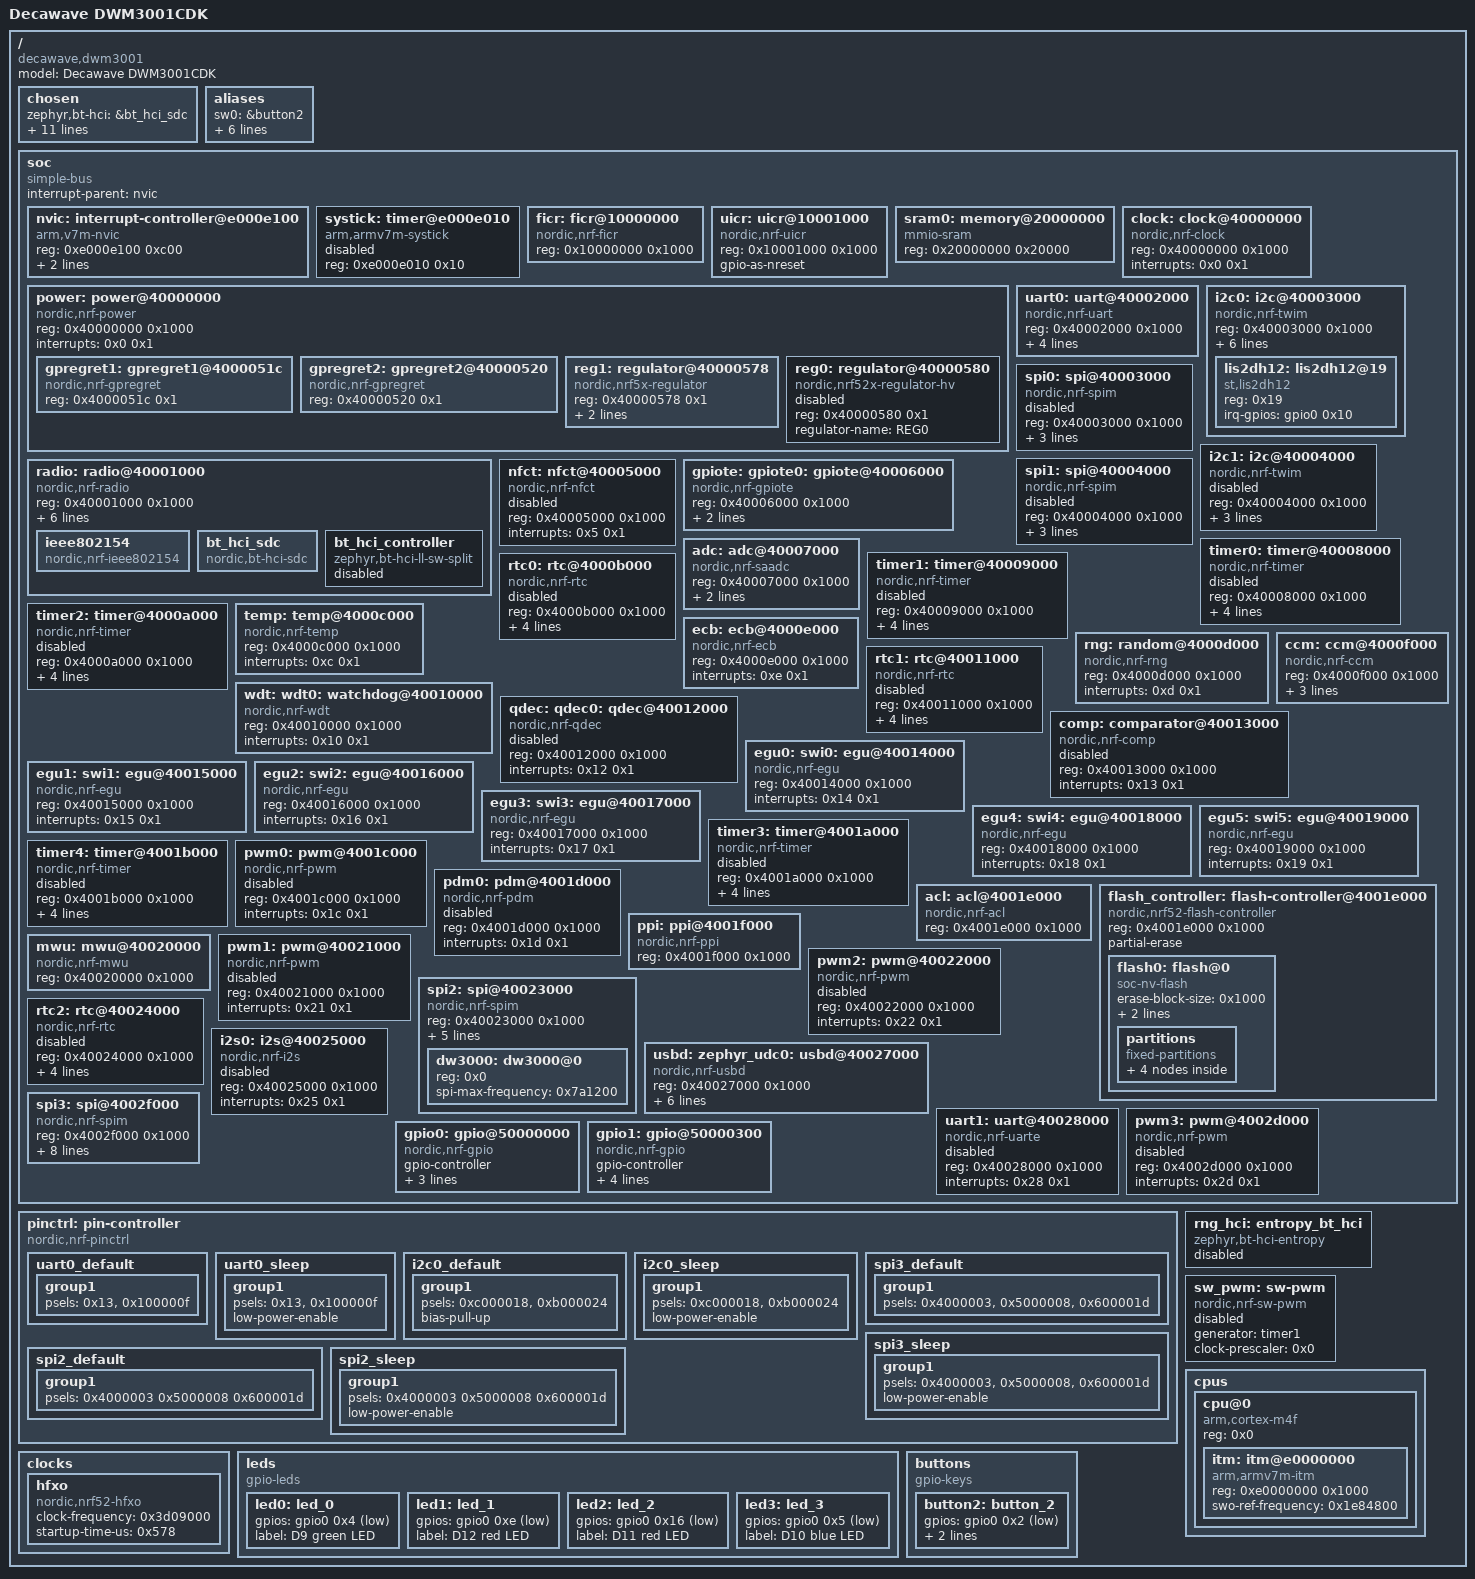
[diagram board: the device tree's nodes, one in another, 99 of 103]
/dts-v1/;

/* node '/' defined in zephyr\dts\common\skeleton.dtsi:9 */
/ {
	#address-cells = < 0x1 >;        /* in zephyr\dts\common\skeleton.dtsi:10 */
	#size-cells = < 0x1 >;           /* in zephyr\dts\common\skeleton.dtsi:11 */
	model = "Decawave DWM3001CDK";   /* in zephyr\boards\qorvo\decawave_dwm3001cdk\decawave_dwm3001cdk.dts:13 */
	compatible = "decawave,dwm3001"; /* in zephyr\boards\qorvo\decawave_dwm3001cdk\decawave_dwm3001cdk.dts:14 */

	/* node '/chosen' defined in zephyr\dts\common\skeleton.dtsi:13 */
	chosen {
		zephyr,bt-hci = &bt_hci_sdc;                 /* in zephyr\dts\arm\nordic\nrf52833.dtsi:14 */
		zephyr,entropy = &rng;                       /* in zephyr\dts\arm\nordic\nrf52833.dtsi:15 */
		zephyr,flash-controller = &flash_controller; /* in zephyr\dts\arm\nordic\nrf52833.dtsi:16 */
		zephyr,console = &uart0;                     /* in zephyr\boards\qorvo\decawave_dwm3001cdk\decawave_dwm3001cdk.dts:17 */
		zephyr,shell-uart = &uart0;                  /* in zephyr\boards\qorvo\decawave_dwm3001cdk\decawave_dwm3001cdk.dts:18 */
		zephyr,uart-mcumgr = &uart0;                 /* in zephyr\boards\qorvo\decawave_dwm3001cdk\decawave_dwm3001cdk.dts:19 */
		zephyr,bt-mon-uart = &uart0;                 /* in zephyr\boards\qorvo\decawave_dwm3001cdk\decawave_dwm3001cdk.dts:20 */
		zephyr,bt-c2h-uart = &uart0;                 /* in zephyr\boards\qorvo\decawave_dwm3001cdk\decawave_dwm3001cdk.dts:21 */
		zephyr,sram = &sram0;                        /* in zephyr\boards\qorvo\decawave_dwm3001cdk\decawave_dwm3001cdk.dts:22 */
		zephyr,flash = &flash0;                      /* in zephyr\boards\qorvo\decawave_dwm3001cdk\decawave_dwm3001cdk.dts:23 */
		zephyr,code-partition = &slot0_partition;    /* in zephyr\boards\qorvo\decawave_dwm3001cdk\decawave_dwm3001cdk.dts:24 */
		zephyr,ieee802154 = &ieee802154;             /* in zephyr\boards\qorvo\decawave_dwm3001cdk\decawave_dwm3001cdk.dts:25 */
	};

	/* node '/aliases' defined in zephyr\dts\common\skeleton.dtsi:15 */
	aliases {
		sw0 = &button2;     /* in zephyr\boards\qorvo\decawave_dwm3001cdk\decawave_dwm3001cdk.dts:69 */
		led0 = &led0;       /* in zephyr\boards\qorvo\decawave_dwm3001cdk\decawave_dwm3001cdk.dts:70 */
		led1 = &led1;       /* in zephyr\boards\qorvo\decawave_dwm3001cdk\decawave_dwm3001cdk.dts:71 */
		led2 = &led2;       /* in zephyr\boards\qorvo\decawave_dwm3001cdk\decawave_dwm3001cdk.dts:72 */
		led3 = &led3;       /* in zephyr\boards\qorvo\decawave_dwm3001cdk\decawave_dwm3001cdk.dts:73 */
		watchdog0 = &wdt0;  /* in zephyr\boards\qorvo\decawave_dwm3001cdk\decawave_dwm3001cdk.dts:74 */
		accel0 = &lis2dh12; /* in zephyr\boards\qorvo\decawave_dwm3001cdk\decawave_dwm3001cdk.dts:75 */
	};

	/* node '/soc' defined in zephyr\dts\arm\armv7-m.dtsi:6 */
	soc {
		#address-cells = < 0x1 >;     /* in zephyr\dts\arm\armv7-m.dtsi:7 */
		#size-cells = < 0x1 >;        /* in zephyr\dts\arm\armv7-m.dtsi:8 */
		interrupt-parent = < &nvic >; /* in zephyr\dts\arm\armv7-m.dtsi:10 */
		ranges;                       /* in zephyr\dts\arm\armv7-m.dtsi:11 */
		compatible = "simple-bus";    /* in zephyr\dts\arm\nordic\nrf52833_qdaa.dtsi:21 */

		/* node '/soc/interrupt-controller@e000e100' defined in zephyr\dts\arm\armv7-m.dtsi:13 */
		nvic: interrupt-controller@e000e100 {
			#address-cells = < 0x1 >;            /* in zephyr\dts\arm\armv7-m.dtsi:14 */
			compatible = "arm,v7m-nvic";         /* in zephyr\dts\arm\armv7-m.dtsi:15 */
			reg = < 0xe000e100 0xc00 >;          /* in zephyr\dts\arm\armv7-m.dtsi:16 */
			interrupt-controller;                /* in zephyr\dts\arm\armv7-m.dtsi:17 */
			#interrupt-cells = < 0x2 >;          /* in zephyr\dts\arm\armv7-m.dtsi:18 */
			arm,num-irq-priority-bits = < 0x3 >; /* in zephyr\dts\arm\nordic\nrf52833.dtsi:581 */
			phandle = < 0x1 >;                   /* in zephyr\dts\arm\armv7-m.dtsi:10 */
		};

		/* node '/soc/timer@e000e010' defined in zephyr\dts\arm\armv7-m.dtsi:21 */
		systick: timer@e000e010 {
			compatible = "arm,armv7m-systick"; /* in zephyr\dts\arm\armv7-m.dtsi:22 */
			reg = < 0xe000e010 0x10 >;         /* in zephyr\dts\arm\armv7-m.dtsi:23 */
			status = "disabled";               /* in zephyr\dts\arm\nordic\nrf52833.dtsi:586 */
		};

		/* node '/soc/ficr@10000000' defined in zephyr\dts\arm\nordic\nrf52833.dtsi:48 */
		ficr: ficr@10000000 {
			compatible = "nordic,nrf-ficr"; /* in zephyr\dts\arm\nordic\nrf52833.dtsi:49 */
			reg = < 0x10000000 0x1000 >;    /* in zephyr\dts\arm\nordic\nrf52833.dtsi:50 */
			#nordic,ficr-cells = < 0x1 >;   /* in zephyr\dts\arm\nordic\nrf52833.dtsi:51 */
			status = "okay";                /* in zephyr\dts\arm\nordic\nrf52833.dtsi:52 */
		};

		/* node '/soc/uicr@10001000' defined in zephyr\dts\arm\nordic\nrf52833.dtsi:55 */
		uicr: uicr@10001000 {
			compatible = "nordic,nrf-uicr";     /* in zephyr\dts\arm\nordic\nrf52833.dtsi:56 */
			reg = < 0x10001000 0x1000 >;        /* in zephyr\dts\arm\nordic\nrf52833.dtsi:57 */
			ranges = < 0x0 0x10001000 0x1000 >; /* in zephyr\dts\arm\nordic\nrf52833.dtsi:58 */
			status = "okay";                    /* in zephyr\dts\arm\nordic\nrf52833.dtsi:59 */
			#address-cells = < 0x1 >;           /* in zephyr\dts\arm\nordic\nrf52833.dtsi:60 */
			#size-cells = < 0x1 >;              /* in zephyr\dts\arm\nordic\nrf52833.dtsi:61 */
			gpio-as-nreset;                     /* in zephyr\boards\qorvo\decawave_dwm3001cdk\decawave_dwm3001cdk.dts:80 */
		};

		/* node '/soc/memory@20000000' defined in zephyr\dts\arm\nordic\nrf52833.dtsi:64 */
		sram0: memory@20000000 {
			compatible = "mmio-sram";            /* in zephyr\dts\arm\nordic\nrf52833.dtsi:65 */
			#address-cells = < 0x1 >;            /* in zephyr\dts\arm\nordic\nrf52833.dtsi:66 */
			#size-cells = < 0x1 >;               /* in zephyr\dts\arm\nordic\nrf52833.dtsi:67 */
			reg = < 0x20000000 0x20000 >;        /* in zephyr\dts\arm\nordic\nrf52833_qdaa.dtsi:15 */
			ranges = < 0x0 0x20000000 0x20000 >; /* in zephyr\dts\arm\nordic\nrf52833_qdaa.dtsi:16 */
		};

		/* node '/soc/clock@40000000' defined in zephyr\dts\arm\nordic\nrf52833.dtsi:70 */
		clock: clock@40000000 {
			compatible = "nordic,nrf-clock"; /* in zephyr\dts\arm\nordic\nrf52833.dtsi:71 */
			reg = < 0x40000000 0x1000 >;     /* in zephyr\dts\arm\nordic\nrf52833.dtsi:72 */
			interrupts = < 0x0 0x1 >;        /* in zephyr\dts\arm\nordic\nrf52833.dtsi:73 */
			status = "okay";                 /* in zephyr\dts\arm\nordic\nrf52833.dtsi:74 */
		};

		/* node '/soc/power@40000000' defined in zephyr\dts\arm\nordic\nrf52833.dtsi:77 */
		power: power@40000000 {
			compatible = "nordic,nrf-power"; /* in zephyr\dts\arm\nordic\nrf52833.dtsi:78 */
			reg = < 0x40000000 0x1000 >;     /* in zephyr\dts\arm\nordic\nrf52833.dtsi:79 */
			interrupts = < 0x0 0x1 >;        /* in zephyr\dts\arm\nordic\nrf52833.dtsi:80 */
			status = "okay";                 /* in zephyr\dts\arm\nordic\nrf52833.dtsi:81 */
			#address-cells = < 0x1 >;        /* in zephyr\dts\arm\nordic\nrf52833.dtsi:82 */
			#size-cells = < 0x1 >;           /* in zephyr\dts\arm\nordic\nrf52833.dtsi:83 */

			/* node '/soc/power@40000000/gpregret1@4000051c' defined in zephyr\dts\arm\nordic\nrf52833.dtsi:85 */
			gpregret1: gpregret1@4000051c {
				#address-cells = < 0x1 >;           /* in zephyr\dts\arm\nordic\nrf52833.dtsi:86 */
				#size-cells = < 0x1 >;              /* in zephyr\dts\arm\nordic\nrf52833.dtsi:87 */
				compatible = "nordic,nrf-gpregret"; /* in zephyr\dts\arm\nordic\nrf52833.dtsi:88 */
				reg = < 0x4000051c 0x1 >;           /* in zephyr\dts\arm\nordic\nrf52833.dtsi:89 */
				status = "okay";                    /* in zephyr\dts\arm\nordic\nrf52833.dtsi:90 */
			};

			/* node '/soc/power@40000000/gpregret2@40000520' defined in zephyr\dts\arm\nordic\nrf52833.dtsi:93 */
			gpregret2: gpregret2@40000520 {
				#address-cells = < 0x1 >;           /* in zephyr\dts\arm\nordic\nrf52833.dtsi:94 */
				#size-cells = < 0x1 >;              /* in zephyr\dts\arm\nordic\nrf52833.dtsi:95 */
				compatible = "nordic,nrf-gpregret"; /* in zephyr\dts\arm\nordic\nrf52833.dtsi:96 */
				reg = < 0x40000520 0x1 >;           /* in zephyr\dts\arm\nordic\nrf52833.dtsi:97 */
				status = "okay";                    /* in zephyr\dts\arm\nordic\nrf52833.dtsi:98 */
			};

			/* node '/soc/power@40000000/regulator@40000578' defined in zephyr\dts\arm\nordic\nrf52833.dtsi:101 */
			reg1: regulator@40000578 {
				compatible = "nordic,nrf5x-regulator"; /* in zephyr\dts\arm\nordic\nrf52833.dtsi:102 */
				reg = < 0x40000578 0x1 >;              /* in zephyr\dts\arm\nordic\nrf52833.dtsi:103 */
				regulator-name = "REG1";               /* in zephyr\dts\arm\nordic\nrf52833.dtsi:104 */
				regulator-initial-mode = < 0x1 >;      /* in zephyr\boards\qorvo\decawave_dwm3001cdk\decawave_dwm3001cdk.dts:168 */
			};

			/* node '/soc/power@40000000/regulator@40000580' defined in zephyr\dts\arm\nordic\nrf52833.dtsi:108 */
			reg0: regulator@40000580 {
				compatible = "nordic,nrf52x-regulator-hv"; /* in zephyr\dts\arm\nordic\nrf52833.dtsi:109 */
				reg = < 0x40000580 0x1 >;                  /* in zephyr\dts\arm\nordic\nrf52833.dtsi:110 */
				regulator-name = "REG0";                   /* in zephyr\dts\arm\nordic\nrf52833.dtsi:111 */
				status = "disabled";                       /* in zephyr\dts\arm\nordic\nrf52833.dtsi:112 */
			};
		};

		/* node '/soc/radio@40001000' defined in zephyr\dts\arm\nordic\nrf52833.dtsi:116 */
		radio: radio@40001000 {
			compatible = "nordic,nrf-radio"; /* in zephyr\dts\arm\nordic\nrf52833.dtsi:117 */
			reg = < 0x40001000 0x1000 >;     /* in zephyr\dts\arm\nordic\nrf52833.dtsi:118 */
			interrupts = < 0x1 0x1 >;        /* in zephyr\dts\arm\nordic\nrf52833.dtsi:119 */
			status = "okay";                 /* in zephyr\dts\arm\nordic\nrf52833.dtsi:120 */
			dfe-supported;                   /* in zephyr\dts\arm\nordic\nrf52833.dtsi:121 */
			ieee802154-supported;            /* in zephyr\dts\arm\nordic\nrf52833.dtsi:122 */
			ble-2mbps-supported;             /* in zephyr\dts\arm\nordic\nrf52833.dtsi:123 */
			ble-coded-phy-supported;         /* in zephyr\dts\arm\nordic\nrf52833.dtsi:124 */
			radio-tx-high-power-supported;   /* in zephyr\dts\arm\nordic\nrf52833.dtsi:125 */

			/* node '/soc/radio@40001000/ieee802154' defined in zephyr\dts\arm\nordic\nrf52833.dtsi:127 */
			ieee802154: ieee802154 {
				compatible = "nordic,nrf-ieee802154"; /* in zephyr\dts\arm\nordic\nrf52833.dtsi:128 */
				status = "okay";                      /* in zephyr\boards\qorvo\decawave_dwm3001cdk\decawave_dwm3001cdk.dts:131 */
			};

			/* node '/soc/radio@40001000/bt_hci_sdc' defined in zephyr\dts\arm\nordic\nrf52833.dtsi:132 */
			bt_hci_sdc: bt_hci_sdc {
				compatible = "nordic,bt-hci-sdc"; /* in zephyr\dts\arm\nordic\nrf52833.dtsi:133 */
				status = "okay";                  /* in zephyr\dts\arm\nordic\nrf52833.dtsi:134 */
			};

			/* node '/soc/radio@40001000/bt_hci_controller' defined in zephyr\dts\arm\nordic\nrf52833.dtsi:136 */
			bt_hci_controller: bt_hci_controller {
				compatible = "zephyr,bt-hci-ll-sw-split"; /* in zephyr\dts\arm\nordic\nrf52833.dtsi:137 */
				status = "disabled";                      /* in zephyr\dts\arm\nordic\nrf52833.dtsi:138 */
			};
		};

		/* node '/soc/uart@40002000' defined in zephyr\dts\arm\nordic\nrf52833.dtsi:142 */
		uart0: uart@40002000 {
			reg = < 0x40002000 0x1000 >;    /* in zephyr\dts\arm\nordic\nrf52833.dtsi:146 */
			interrupts = < 0x2 0x1 >;       /* in zephyr\dts\arm\nordic\nrf52833.dtsi:147 */
			status = "okay";                /* in zephyr\boards\qorvo\decawave_dwm3001cdk\decawave_dwm3001cdk.dts:92 */
			compatible = "nordic,nrf-uart"; /* in zephyr\boards\qorvo\decawave_dwm3001cdk\decawave_dwm3001cdk.dts:93 */
			current-speed = < 0x1c200 >;    /* in zephyr\boards\qorvo\decawave_dwm3001cdk\decawave_dwm3001cdk.dts:94 */
			pinctrl-0 = < &uart0_default >; /* in zephyr\boards\qorvo\decawave_dwm3001cdk\decawave_dwm3001cdk.dts:95 */
			pinctrl-1 = < &uart0_sleep >;   /* in zephyr\boards\qorvo\decawave_dwm3001cdk\decawave_dwm3001cdk.dts:96 */
			pinctrl-names = "default",
			                "sleep";        /* in zephyr\boards\qorvo\decawave_dwm3001cdk\decawave_dwm3001cdk.dts:97 */
		};

		/* node '/soc/i2c@40003000' defined in zephyr\dts\arm\nordic\nrf52833.dtsi:151 */
		i2c0: i2c@40003000 {
			#address-cells = < 0x1 >;       /* in zephyr\dts\arm\nordic\nrf52833.dtsi:160 */
			#size-cells = < 0x0 >;          /* in zephyr\dts\arm\nordic\nrf52833.dtsi:161 */
			reg = < 0x40003000 0x1000 >;    /* in zephyr\dts\arm\nordic\nrf52833.dtsi:162 */
			interrupts = < 0x3 0x1 >;       /* in zephyr\dts\arm\nordic\nrf52833.dtsi:163 */
			easydma-maxcnt-bits = < 0x10 >; /* in zephyr\dts\arm\nordic\nrf52833.dtsi:164 */
			zephyr,pm-device-runtime-auto;  /* in zephyr\dts\arm\nordic\nrf52833.dtsi:166 */
			compatible = "nordic,nrf-twim"; /* in zephyr\boards\qorvo\decawave_dwm3001cdk\decawave_dwm3001cdk.dts:105 */
			status = "okay";                /* in zephyr\boards\qorvo\decawave_dwm3001cdk\decawave_dwm3001cdk.dts:106 */
			clock-frequency = < 0x61a80 >;  /* in zephyr\boards\qorvo\decawave_dwm3001cdk\decawave_dwm3001cdk.dts:107 */
			pinctrl-0 = < &i2c0_default >;  /* in zephyr\boards\qorvo\decawave_dwm3001cdk\decawave_dwm3001cdk.dts:109 */
			pinctrl-1 = < &i2c0_sleep >;    /* in zephyr\boards\qorvo\decawave_dwm3001cdk\decawave_dwm3001cdk.dts:110 */
			pinctrl-names = "default",
			                "sleep";        /* in zephyr\boards\qorvo\decawave_dwm3001cdk\decawave_dwm3001cdk.dts:111 */

			/* node '/soc/i2c@40003000/lis2dh12@19' defined in zephyr\boards\qorvo\decawave_dwm3001cdk\decawave_dwm3001cdk.dts:113 */
			lis2dh12: lis2dh12@19 {
				compatible = "st,lis2dh12",
				             "st,lis2dh";        /* in zephyr\boards\qorvo\decawave_dwm3001cdk\decawave_dwm3001cdk.dts:114 */
				reg = < 0x19 >;                  /* in zephyr\boards\qorvo\decawave_dwm3001cdk\decawave_dwm3001cdk.dts:115 */
				irq-gpios = < &gpio0 0x10 0x0 >; /* in zephyr\boards\qorvo\decawave_dwm3001cdk\decawave_dwm3001cdk.dts:116 */
			};
		};

		/* node '/soc/spi@40003000' defined in zephyr\dts\arm\nordic\nrf52833.dtsi:169 */
		spi0: spi@40003000 {
			compatible = "nordic,nrf-spim"; /* in zephyr\dts\arm\nordic\nrf52833.dtsi:177 */
			#address-cells = < 0x1 >;       /* in zephyr\dts\arm\nordic\nrf52833.dtsi:178 */
			#size-cells = < 0x0 >;          /* in zephyr\dts\arm\nordic\nrf52833.dtsi:179 */
			reg = < 0x40003000 0x1000 >;    /* in zephyr\dts\arm\nordic\nrf52833.dtsi:180 */
			interrupts = < 0x3 0x1 >;       /* in zephyr\dts\arm\nordic\nrf52833.dtsi:181 */
			max-frequency = < 0x7a1200 >;   /* in zephyr\dts\arm\nordic\nrf52833.dtsi:182 */
			easydma-maxcnt-bits = < 0x10 >; /* in zephyr\dts\arm\nordic\nrf52833.dtsi:183 */
			status = "disabled";            /* in zephyr\dts\arm\nordic\nrf52833.dtsi:184 */
		};

		/* node '/soc/i2c@40004000' defined in zephyr\dts\arm\nordic\nrf52833.dtsi:187 */
		i2c1: i2c@40004000 {
			compatible = "nordic,nrf-twim"; /* in zephyr\dts\arm\nordic\nrf52833.dtsi:195 */
			#address-cells = < 0x1 >;       /* in zephyr\dts\arm\nordic\nrf52833.dtsi:196 */
			#size-cells = < 0x0 >;          /* in zephyr\dts\arm\nordic\nrf52833.dtsi:197 */
			reg = < 0x40004000 0x1000 >;    /* in zephyr\dts\arm\nordic\nrf52833.dtsi:198 */
			interrupts = < 0x4 0x1 >;       /* in zephyr\dts\arm\nordic\nrf52833.dtsi:199 */
			easydma-maxcnt-bits = < 0x10 >; /* in zephyr\dts\arm\nordic\nrf52833.dtsi:200 */
			status = "disabled";            /* in zephyr\dts\arm\nordic\nrf52833.dtsi:201 */
			zephyr,pm-device-runtime-auto;  /* in zephyr\dts\arm\nordic\nrf52833.dtsi:202 */
		};

		/* node '/soc/spi@40004000' defined in zephyr\dts\arm\nordic\nrf52833.dtsi:205 */
		spi1: spi@40004000 {
			compatible = "nordic,nrf-spim"; /* in zephyr\dts\arm\nordic\nrf52833.dtsi:213 */
			#address-cells = < 0x1 >;       /* in zephyr\dts\arm\nordic\nrf52833.dtsi:214 */
			#size-cells = < 0x0 >;          /* in zephyr\dts\arm\nordic\nrf52833.dtsi:215 */
			reg = < 0x40004000 0x1000 >;    /* in zephyr\dts\arm\nordic\nrf52833.dtsi:216 */
			interrupts = < 0x4 0x1 >;       /* in zephyr\dts\arm\nordic\nrf52833.dtsi:217 */
			max-frequency = < 0x7a1200 >;   /* in zephyr\dts\arm\nordic\nrf52833.dtsi:218 */
			easydma-maxcnt-bits = < 0x10 >; /* in zephyr\dts\arm\nordic\nrf52833.dtsi:219 */
			status = "disabled";            /* in zephyr\dts\arm\nordic\nrf52833.dtsi:220 */
		};

		/* node '/soc/nfct@40005000' defined in zephyr\dts\arm\nordic\nrf52833.dtsi:223 */
		nfct: nfct@40005000 {
			compatible = "nordic,nrf-nfct"; /* in zephyr\dts\arm\nordic\nrf52833.dtsi:224 */
			reg = < 0x40005000 0x1000 >;    /* in zephyr\dts\arm\nordic\nrf52833.dtsi:225 */
			interrupts = < 0x5 0x1 >;       /* in zephyr\dts\arm\nordic\nrf52833.dtsi:226 */
			status = "disabled";            /* in zephyr\dts\arm\nordic\nrf52833.dtsi:227 */
		};

		/* node '/soc/gpiote@40006000' defined in zephyr\dts\arm\nordic\nrf52833.dtsi:230 */
		gpiote: gpiote0: gpiote@40006000 {
			compatible = "nordic,nrf-gpiote"; /* in zephyr\dts\arm\nordic\nrf52833.dtsi:231 */
			reg = < 0x40006000 0x1000 >;      /* in zephyr\dts\arm\nordic\nrf52833.dtsi:232 */
			interrupts = < 0x6 0x5 >;         /* in zephyr\dts\arm\nordic\nrf52833.dtsi:233 */
			instance = < 0x0 >;               /* in zephyr\dts\arm\nordic\nrf52833.dtsi:235 */
			status = "okay";                  /* in zephyr\boards\qorvo\decawave_dwm3001cdk\decawave_dwm3001cdk.dts:84 */
			phandle = < 0xc >;                /* in zephyr\dts\arm\nordic\nrf52833.dtsi:563 */
		};

		/* node '/soc/adc@40007000' defined in zephyr\dts\arm\nordic\nrf52833.dtsi:238 */
		adc: adc@40007000 {
			compatible = "nordic,nrf-saadc"; /* in zephyr\dts\arm\nordic\nrf52833.dtsi:239 */
			reg = < 0x40007000 0x1000 >;     /* in zephyr\dts\arm\nordic\nrf52833.dtsi:240 */
			interrupts = < 0x7 0x1 >;        /* in zephyr\dts\arm\nordic\nrf52833.dtsi:241 */
			#io-channel-cells = < 0x1 >;     /* in zephyr\dts\arm\nordic\nrf52833.dtsi:243 */
			zephyr,pm-device-runtime-auto;   /* in zephyr\dts\arm\nordic\nrf52833.dtsi:244 */
			status = "okay";                 /* in zephyr\boards\qorvo\decawave_dwm3001cdk\decawave_dwm3001cdk.dts:172 */
		};

		/* node '/soc/timer@40008000' defined in zephyr\dts\arm\nordic\nrf52833.dtsi:247 */
		timer0: timer@40008000 {
			compatible = "nordic,nrf-timer"; /* in zephyr\dts\arm\nordic\nrf52833.dtsi:248 */
			status = "disabled";             /* in zephyr\dts\arm\nordic\nrf52833.dtsi:249 */
			reg = < 0x40008000 0x1000 >;     /* in zephyr\dts\arm\nordic\nrf52833.dtsi:250 */
			cc-num = < 0x4 >;                /* in zephyr\dts\arm\nordic\nrf52833.dtsi:251 */
			max-bit-width = < 0x20 >;        /* in zephyr\dts\arm\nordic\nrf52833.dtsi:252 */
			interrupts = < 0x8 0x1 >;        /* in zephyr\dts\arm\nordic\nrf52833.dtsi:253 */
			prescaler = < 0x0 >;             /* in zephyr\dts\arm\nordic\nrf52833.dtsi:254 */
		};

		/* node '/soc/timer@40009000' defined in zephyr\dts\arm\nordic\nrf52833.dtsi:257 */
		timer1: timer@40009000 {
			compatible = "nordic,nrf-timer"; /* in zephyr\dts\arm\nordic\nrf52833.dtsi:258 */
			status = "disabled";             /* in zephyr\dts\arm\nordic\nrf52833.dtsi:259 */
			reg = < 0x40009000 0x1000 >;     /* in zephyr\dts\arm\nordic\nrf52833.dtsi:260 */
			cc-num = < 0x4 >;                /* in zephyr\dts\arm\nordic\nrf52833.dtsi:261 */
			max-bit-width = < 0x20 >;        /* in zephyr\dts\arm\nordic\nrf52833.dtsi:262 */
			interrupts = < 0x9 0x1 >;        /* in zephyr\dts\arm\nordic\nrf52833.dtsi:263 */
			prescaler = < 0x0 >;             /* in zephyr\dts\arm\nordic\nrf52833.dtsi:264 */
			phandle = < 0xd >;               /* in zephyr\dts\vendor\nordic\nrf_common.dtsi:42 */
		};

		/* node '/soc/timer@4000a000' defined in zephyr\dts\arm\nordic\nrf52833.dtsi:267 */
		timer2: timer@4000a000 {
			compatible = "nordic,nrf-timer"; /* in zephyr\dts\arm\nordic\nrf52833.dtsi:268 */
			status = "disabled";             /* in zephyr\dts\arm\nordic\nrf52833.dtsi:269 */
			reg = < 0x4000a000 0x1000 >;     /* in zephyr\dts\arm\nordic\nrf52833.dtsi:270 */
			cc-num = < 0x4 >;                /* in zephyr\dts\arm\nordic\nrf52833.dtsi:271 */
			max-bit-width = < 0x20 >;        /* in zephyr\dts\arm\nordic\nrf52833.dtsi:272 */
			interrupts = < 0xa 0x1 >;        /* in zephyr\dts\arm\nordic\nrf52833.dtsi:273 */
			prescaler = < 0x0 >;             /* in zephyr\dts\arm\nordic\nrf52833.dtsi:274 */
		};

		/* node '/soc/rtc@4000b000' defined in zephyr\dts\arm\nordic\nrf52833.dtsi:277 */
		rtc0: rtc@4000b000 {
			compatible = "nordic,nrf-rtc"; /* in zephyr\dts\arm\nordic\nrf52833.dtsi:278 */
			reg = < 0x4000b000 0x1000 >;   /* in zephyr\dts\arm\nordic\nrf52833.dtsi:279 */
			cc-num = < 0x3 >;              /* in zephyr\dts\arm\nordic\nrf52833.dtsi:280 */
			interrupts = < 0xb 0x1 >;      /* in zephyr\dts\arm\nordic\nrf52833.dtsi:281 */
			status = "disabled";           /* in zephyr\dts\arm\nordic\nrf52833.dtsi:282 */
			clock-frequency = < 0x8000 >;  /* in zephyr\dts\arm\nordic\nrf52833.dtsi:283 */
			prescaler = < 0x1 >;           /* in zephyr\dts\arm\nordic\nrf52833.dtsi:284 */
		};

		/* node '/soc/temp@4000c000' defined in zephyr\dts\arm\nordic\nrf52833.dtsi:287 */
		temp: temp@4000c000 {
			compatible = "nordic,nrf-temp"; /* in zephyr\dts\arm\nordic\nrf52833.dtsi:288 */
			reg = < 0x4000c000 0x1000 >;    /* in zephyr\dts\arm\nordic\nrf52833.dtsi:289 */
			interrupts = < 0xc 0x1 >;       /* in zephyr\dts\arm\nordic\nrf52833.dtsi:290 */
			status = "okay";                /* in zephyr\dts\arm\nordic\nrf52833.dtsi:291 */
		};

		/* node '/soc/random@4000d000' defined in zephyr\dts\arm\nordic\nrf52833.dtsi:294 */
		rng: random@4000d000 {
			compatible = "nordic,nrf-rng"; /* in zephyr\dts\arm\nordic\nrf52833.dtsi:295 */
			reg = < 0x4000d000 0x1000 >;   /* in zephyr\dts\arm\nordic\nrf52833.dtsi:296 */
			interrupts = < 0xd 0x1 >;      /* in zephyr\dts\arm\nordic\nrf52833.dtsi:297 */
			status = "okay";               /* in zephyr\dts\arm\nordic\nrf52833.dtsi:298 */
		};

		/* node '/soc/ecb@4000e000' defined in zephyr\dts\arm\nordic\nrf52833.dtsi:301 */
		ecb: ecb@4000e000 {
			compatible = "nordic,nrf-ecb"; /* in zephyr\dts\arm\nordic\nrf52833.dtsi:302 */
			reg = < 0x4000e000 0x1000 >;   /* in zephyr\dts\arm\nordic\nrf52833.dtsi:303 */
			interrupts = < 0xe 0x1 >;      /* in zephyr\dts\arm\nordic\nrf52833.dtsi:304 */
			status = "okay";               /* in zephyr\dts\arm\nordic\nrf52833.dtsi:305 */
		};

		/* node '/soc/ccm@4000f000' defined in zephyr\dts\arm\nordic\nrf52833.dtsi:308 */
		ccm: ccm@4000f000 {
			compatible = "nordic,nrf-ccm"; /* in zephyr\dts\arm\nordic\nrf52833.dtsi:309 */
			reg = < 0x4000f000 0x1000 >;   /* in zephyr\dts\arm\nordic\nrf52833.dtsi:310 */
			interrupts = < 0xf 0x1 >;      /* in zephyr\dts\arm\nordic\nrf52833.dtsi:311 */
			length-field-length-8-bits;    /* in zephyr\dts\arm\nordic\nrf52833.dtsi:312 */
			headermask-supported;          /* in zephyr\dts\arm\nordic\nrf52833.dtsi:313 */
			status = "okay";               /* in zephyr\dts\arm\nordic\nrf52833.dtsi:314 */
		};

		/* node '/soc/watchdog@40010000' defined in zephyr\dts\arm\nordic\nrf52833.dtsi:317 */
		wdt: wdt0: watchdog@40010000 {
			compatible = "nordic,nrf-wdt"; /* in zephyr\dts\arm\nordic\nrf52833.dtsi:318 */
			reg = < 0x40010000 0x1000 >;   /* in zephyr\dts\arm\nordic\nrf52833.dtsi:319 */
			interrupts = < 0x10 0x1 >;     /* in zephyr\dts\arm\nordic\nrf52833.dtsi:320 */
			status = "okay";               /* in zephyr\dts\arm\nordic\nrf52833.dtsi:321 */
		};

		/* node '/soc/rtc@40011000' defined in zephyr\dts\arm\nordic\nrf52833.dtsi:324 */
		rtc1: rtc@40011000 {
			compatible = "nordic,nrf-rtc"; /* in zephyr\dts\arm\nordic\nrf52833.dtsi:325 */
			reg = < 0x40011000 0x1000 >;   /* in zephyr\dts\arm\nordic\nrf52833.dtsi:326 */
			cc-num = < 0x4 >;              /* in zephyr\dts\arm\nordic\nrf52833.dtsi:327 */
			interrupts = < 0x11 0x1 >;     /* in zephyr\dts\arm\nordic\nrf52833.dtsi:328 */
			status = "disabled";           /* in zephyr\dts\arm\nordic\nrf52833.dtsi:329 */
			clock-frequency = < 0x8000 >;  /* in zephyr\dts\arm\nordic\nrf52833.dtsi:330 */
			prescaler = < 0x1 >;           /* in zephyr\dts\arm\nordic\nrf52833.dtsi:331 */
		};

		/* node '/soc/qdec@40012000' defined in zephyr\dts\arm\nordic\nrf52833.dtsi:334 */
		qdec: qdec0: qdec@40012000 {
			compatible = "nordic,nrf-qdec"; /* in zephyr\dts\arm\nordic\nrf52833.dtsi:335 */
			reg = < 0x40012000 0x1000 >;    /* in zephyr\dts\arm\nordic\nrf52833.dtsi:336 */
			interrupts = < 0x12 0x1 >;      /* in zephyr\dts\arm\nordic\nrf52833.dtsi:337 */
			status = "disabled";            /* in zephyr\dts\arm\nordic\nrf52833.dtsi:338 */
		};

		/* node '/soc/comparator@40013000' defined in zephyr\dts\arm\nordic\nrf52833.dtsi:341 */
		comp: comparator@40013000 {
			compatible = "nordic,nrf-comp"; /* in zephyr\dts\arm\nordic\nrf52833.dtsi:346 */
			reg = < 0x40013000 0x1000 >;    /* in zephyr\dts\arm\nordic\nrf52833.dtsi:347 */
			interrupts = < 0x13 0x1 >;      /* in zephyr\dts\arm\nordic\nrf52833.dtsi:348 */
			status = "disabled";            /* in zephyr\dts\arm\nordic\nrf52833.dtsi:349 */
		};

		/* node '/soc/egu@40014000' defined in zephyr\dts\arm\nordic\nrf52833.dtsi:352 */
		egu0: swi0: egu@40014000 {
			compatible = "nordic,nrf-egu",
			             "nordic,nrf-swi"; /* in zephyr\dts\arm\nordic\nrf52833.dtsi:353 */
			reg = < 0x40014000 0x1000 >;   /* in zephyr\dts\arm\nordic\nrf52833.dtsi:354 */
			interrupts = < 0x14 0x1 >;     /* in zephyr\dts\arm\nordic\nrf52833.dtsi:355 */
			status = "okay";               /* in zephyr\dts\arm\nordic\nrf52833.dtsi:356 */
		};

		/* node '/soc/egu@40015000' defined in zephyr\dts\arm\nordic\nrf52833.dtsi:359 */
		egu1: swi1: egu@40015000 {
			compatible = "nordic,nrf-egu",
			             "nordic,nrf-swi"; /* in zephyr\dts\arm\nordic\nrf52833.dtsi:360 */
			reg = < 0x40015000 0x1000 >;   /* in zephyr\dts\arm\nordic\nrf52833.dtsi:361 */
			interrupts = < 0x15 0x1 >;     /* in zephyr\dts\arm\nordic\nrf52833.dtsi:362 */
			status = "okay";               /* in zephyr\dts\arm\nordic\nrf52833.dtsi:363 */
		};

		/* node '/soc/egu@40016000' defined in zephyr\dts\arm\nordic\nrf52833.dtsi:366 */
		egu2: swi2: egu@40016000 {
			compatible = "nordic,nrf-egu",
			             "nordic,nrf-swi"; /* in zephyr\dts\arm\nordic\nrf52833.dtsi:367 */
			reg = < 0x40016000 0x1000 >;   /* in zephyr\dts\arm\nordic\nrf52833.dtsi:368 */
			interrupts = < 0x16 0x1 >;     /* in zephyr\dts\arm\nordic\nrf52833.dtsi:369 */
			status = "okay";               /* in zephyr\dts\arm\nordic\nrf52833.dtsi:370 */
		};

		/* node '/soc/egu@40017000' defined in zephyr\dts\arm\nordic\nrf52833.dtsi:373 */
		egu3: swi3: egu@40017000 {
			compatible = "nordic,nrf-egu",
			             "nordic,nrf-swi"; /* in zephyr\dts\arm\nordic\nrf52833.dtsi:374 */
			reg = < 0x40017000 0x1000 >;   /* in zephyr\dts\arm\nordic\nrf52833.dtsi:375 */
			interrupts = < 0x17 0x1 >;     /* in zephyr\dts\arm\nordic\nrf52833.dtsi:376 */
			status = "okay";               /* in zephyr\dts\arm\nordic\nrf52833.dtsi:377 */
		};

		/* node '/soc/egu@40018000' defined in zephyr\dts\arm\nordic\nrf52833.dtsi:380 */
		egu4: swi4: egu@40018000 {
			compatible = "nordic,nrf-egu",
			             "nordic,nrf-swi"; /* in zephyr\dts\arm\nordic\nrf52833.dtsi:381 */
			reg = < 0x40018000 0x1000 >;   /* in zephyr\dts\arm\nordic\nrf52833.dtsi:382 */
			interrupts = < 0x18 0x1 >;     /* in zephyr\dts\arm\nordic\nrf52833.dtsi:383 */
			status = "okay";               /* in zephyr\dts\arm\nordic\nrf52833.dtsi:384 */
		};

		/* node '/soc/egu@40019000' defined in zephyr\dts\arm\nordic\nrf52833.dtsi:387 */
		egu5: swi5: egu@40019000 {
			compatible = "nordic,nrf-egu",
			             "nordic,nrf-swi"; /* in zephyr\dts\arm\nordic\nrf52833.dtsi:388 */
			reg = < 0x40019000 0x1000 >;   /* in zephyr\dts\arm\nordic\nrf52833.dtsi:389 */
			interrupts = < 0x19 0x1 >;     /* in zephyr\dts\arm\nordic\nrf52833.dtsi:390 */
			status = "okay";               /* in zephyr\dts\arm\nordic\nrf52833.dtsi:391 */
		};

		/* node '/soc/timer@4001a000' defined in zephyr\dts\arm\nordic\nrf52833.dtsi:394 */
		timer3: timer@4001a000 {
			compatible = "nordic,nrf-timer"; /* in zephyr\dts\arm\nordic\nrf52833.dtsi:395 */
			status = "disabled";             /* in zephyr\dts\arm\nordic\nrf52833.dtsi:396 */
			reg = < 0x4001a000 0x1000 >;     /* in zephyr\dts\arm\nordic\nrf52833.dtsi:397 */
			cc-num = < 0x6 >;                /* in zephyr\dts\arm\nordic\nrf52833.dtsi:398 */
			max-bit-width = < 0x20 >;        /* in zephyr\dts\arm\nordic\nrf52833.dtsi:399 */
			interrupts = < 0x1a 0x1 >;       /* in zephyr\dts\arm\nordic\nrf52833.dtsi:400 */
			prescaler = < 0x0 >;             /* in zephyr\dts\arm\nordic\nrf52833.dtsi:401 */
		};

		/* node '/soc/timer@4001b000' defined in zephyr\dts\arm\nordic\nrf52833.dtsi:404 */
		timer4: timer@4001b000 {
			compatible = "nordic,nrf-timer"; /* in zephyr\dts\arm\nordic\nrf52833.dtsi:405 */
			status = "disabled";             /* in zephyr\dts\arm\nordic\nrf52833.dtsi:406 */
			reg = < 0x4001b000 0x1000 >;     /* in zephyr\dts\arm\nordic\nrf52833.dtsi:407 */
			cc-num = < 0x6 >;                /* in zephyr\dts\arm\nordic\nrf52833.dtsi:408 */
			max-bit-width = < 0x20 >;        /* in zephyr\dts\arm\nordic\nrf52833.dtsi:409 */
			interrupts = < 0x1b 0x1 >;       /* in zephyr\dts\arm\nordic\nrf52833.dtsi:410 */
			prescaler = < 0x0 >;             /* in zephyr\dts\arm\nordic\nrf52833.dtsi:411 */
		};

		/* node '/soc/pwm@4001c000' defined in zephyr\dts\arm\nordic\nrf52833.dtsi:414 */
		pwm0: pwm@4001c000 {
			compatible = "nordic,nrf-pwm"; /* in zephyr\dts\arm\nordic\nrf52833.dtsi:415 */
			reg = < 0x4001c000 0x1000 >;   /* in zephyr\dts\arm\nordic\nrf52833.dtsi:416 */
			interrupts = < 0x1c 0x1 >;     /* in zephyr\dts\arm\nordic\nrf52833.dtsi:417 */
			status = "disabled";           /* in zephyr\dts\arm\nordic\nrf52833.dtsi:418 */
			#pwm-cells = < 0x3 >;          /* in zephyr\dts\arm\nordic\nrf52833.dtsi:419 */
		};

		/* node '/soc/pdm@4001d000' defined in zephyr\dts\arm\nordic\nrf52833.dtsi:422 */
		pdm0: pdm@4001d000 {
			compatible = "nordic,nrf-pdm"; /* in zephyr\dts\arm\nordic\nrf52833.dtsi:423 */
			reg = < 0x4001d000 0x1000 >;   /* in zephyr\dts\arm\nordic\nrf52833.dtsi:424 */
			interrupts = < 0x1d 0x1 >;     /* in zephyr\dts\arm\nordic\nrf52833.dtsi:425 */
			status = "disabled";           /* in zephyr\dts\arm\nordic\nrf52833.dtsi:426 */
		};

		/* node '/soc/acl@4001e000' defined in zephyr\dts\arm\nordic\nrf52833.dtsi:429 */
		acl: acl@4001e000 {
			compatible = "nordic,nrf-acl"; /* in zephyr\dts\arm\nordic\nrf52833.dtsi:430 */
			reg = < 0x4001e000 0x1000 >;   /* in zephyr\dts\arm\nordic\nrf52833.dtsi:431 */
			status = "okay";               /* in zephyr\dts\arm\nordic\nrf52833.dtsi:432 */
		};

		/* node '/soc/flash-controller@4001e000' defined in zephyr\dts\arm\nordic\nrf52833.dtsi:435 */
		flash_controller: flash-controller@4001e000 {
			compatible = "nordic,nrf52-flash-controller"; /* in zephyr\dts\arm\nordic\nrf52833.dtsi:436 */
			reg = < 0x4001e000 0x1000 >;                  /* in zephyr\dts\arm\nordic\nrf52833.dtsi:437 */
			partial-erase;                                /* in zephyr\dts\arm\nordic\nrf52833.dtsi:438 */
			#address-cells = < 0x1 >;                     /* in zephyr\dts\arm\nordic\nrf52833.dtsi:440 */
			#size-cells = < 0x1 >;                        /* in zephyr\dts\arm\nordic\nrf52833.dtsi:441 */

			/* node '/soc/flash-controller@4001e000/flash@0' defined in zephyr\dts\arm\nordic\nrf52833.dtsi:443 */
			flash0: flash@0 {
				compatible = "soc-nv-flash";   /* in zephyr\dts\arm\nordic\nrf52833.dtsi:444 */
				erase-block-size = < 0x1000 >; /* in zephyr\dts\arm\nordic\nrf52833.dtsi:445 */
				write-block-size = < 0x4 >;    /* in zephyr\dts\arm\nordic\nrf52833.dtsi:446 */
				reg = < 0x0 0x80000 >;         /* in zephyr\dts\arm\nordic\nrf52833_qdaa.dtsi:11 */

				/* node '/soc/flash-controller@4001e000/flash@0/partitions' defined in zephyr\boards\qorvo\decawave_dwm3001cdk\decawave_dwm3001cdk.dts:135 */
				partitions {
					compatible = "fixed-partitions"; /* in zephyr\boards\qorvo\decawave_dwm3001cdk\decawave_dwm3001cdk.dts:136 */
					#address-cells = < 0x1 >;        /* in zephyr\boards\qorvo\decawave_dwm3001cdk\decawave_dwm3001cdk.dts:137 */
					#size-cells = < 0x1 >;           /* in zephyr\boards\qorvo\decawave_dwm3001cdk\decawave_dwm3001cdk.dts:138 */

					/* node '/soc/flash-controller@4001e000/flash@0/partitions/partition@0' defined in zephyr\boards\qorvo\decawave_dwm3001cdk\decawave_dwm3001cdk.dts:140 */
					boot_partition: partition@0 {
						label = "mcuboot";    /* in zephyr\boards\qorvo\decawave_dwm3001cdk\decawave_dwm3001cdk.dts:141 */
						reg = < 0x0 0xc000 >; /* in zephyr\boards\qorvo\decawave_dwm3001cdk\decawave_dwm3001cdk.dts:142 */
					};

					/* node '/soc/flash-controller@4001e000/flash@0/partitions/partition@c000' defined in zephyr\boards\qorvo\decawave_dwm3001cdk\decawave_dwm3001cdk.dts:145 */
					slot0_partition: partition@c000 {
						label = "image-0";        /* in zephyr\boards\qorvo\decawave_dwm3001cdk\decawave_dwm3001cdk.dts:146 */
						reg = < 0xc000 0x38000 >; /* in zephyr\boards\qorvo\decawave_dwm3001cdk\decawave_dwm3001cdk.dts:147 */
					};

					/* node '/soc/flash-controller@4001e000/flash@0/partitions/partition@44000' defined in zephyr\boards\qorvo\decawave_dwm3001cdk\decawave_dwm3001cdk.dts:150 */
					slot1_partition: partition@44000 {
						label = "image-1";         /* in zephyr\boards\qorvo\decawave_dwm3001cdk\decawave_dwm3001cdk.dts:151 */
						reg = < 0x44000 0x36000 >; /* in zephyr\boards\qorvo\decawave_dwm3001cdk\decawave_dwm3001cdk.dts:152 */
					};

					/* node '/soc/flash-controller@4001e000/flash@0/partitions/partition@7a000' defined in zephyr\boards\qorvo\decawave_dwm3001cdk\decawave_dwm3001cdk.dts:155 */
					storage_partition: partition@7a000 {
						label = "storage";        /* in zephyr\boards\qorvo\decawave_dwm3001cdk\decawave_dwm3001cdk.dts:156 */
						reg = < 0x7a000 0x6000 >; /* in zephyr\boards\qorvo\decawave_dwm3001cdk\decawave_dwm3001cdk.dts:157 */
					};
				};
			};
		};

		/* node '/soc/ppi@4001f000' defined in zephyr\dts\arm\nordic\nrf52833.dtsi:450 */
		ppi: ppi@4001f000 {
			compatible = "nordic,nrf-ppi"; /* in zephyr\dts\arm\nordic\nrf52833.dtsi:451 */
			reg = < 0x4001f000 0x1000 >;   /* in zephyr\dts\arm\nordic\nrf52833.dtsi:452 */
			status = "okay";               /* in zephyr\dts\arm\nordic\nrf52833.dtsi:453 */
		};

		/* node '/soc/mwu@40020000' defined in zephyr\dts\arm\nordic\nrf52833.dtsi:456 */
		mwu: mwu@40020000 {
			compatible = "nordic,nrf-mwu"; /* in zephyr\dts\arm\nordic\nrf52833.dtsi:457 */
			reg = < 0x40020000 0x1000 >;   /* in zephyr\dts\arm\nordic\nrf52833.dtsi:458 */
			status = "okay";               /* in zephyr\dts\arm\nordic\nrf52833.dtsi:459 */
		};

		/* node '/soc/pwm@40021000' defined in zephyr\dts\arm\nordic\nrf52833.dtsi:462 */
		pwm1: pwm@40021000 {
			compatible = "nordic,nrf-pwm"; /* in zephyr\dts\arm\nordic\nrf52833.dtsi:463 */
			reg = < 0x40021000 0x1000 >;   /* in zephyr\dts\arm\nordic\nrf52833.dtsi:464 */
			interrupts = < 0x21 0x1 >;     /* in zephyr\dts\arm\nordic\nrf52833.dtsi:465 */
			status = "disabled";           /* in zephyr\dts\arm\nordic\nrf52833.dtsi:466 */
			#pwm-cells = < 0x3 >;          /* in zephyr\dts\arm\nordic\nrf52833.dtsi:467 */
		};

		/* node '/soc/pwm@40022000' defined in zephyr\dts\arm\nordic\nrf52833.dtsi:470 */
		pwm2: pwm@40022000 {
			compatible = "nordic,nrf-pwm"; /* in zephyr\dts\arm\nordic\nrf52833.dtsi:471 */
			reg = < 0x40022000 0x1000 >;   /* in zephyr\dts\arm\nordic\nrf52833.dtsi:472 */
			interrupts = < 0x22 0x1 >;     /* in zephyr\dts\arm\nordic\nrf52833.dtsi:473 */
			status = "disabled";           /* in zephyr\dts\arm\nordic\nrf52833.dtsi:474 */
			#pwm-cells = < 0x3 >;          /* in zephyr\dts\arm\nordic\nrf52833.dtsi:475 */
		};

		/* node '/soc/spi@40023000' defined in zephyr\dts\arm\nordic\nrf52833.dtsi:478 */
		spi2: spi@40023000 {
			#address-cells = < 0x1 >;       /* in zephyr\dts\arm\nordic\nrf52833.dtsi:487 */
			#size-cells = < 0x0 >;          /* in zephyr\dts\arm\nordic\nrf52833.dtsi:488 */
			reg = < 0x40023000 0x1000 >;    /* in zephyr\dts\arm\nordic\nrf52833.dtsi:489 */
			interrupts = < 0x23 0x1 >;      /* in zephyr\dts\arm\nordic\nrf52833.dtsi:490 */
			max-frequency = < 0x7a1200 >;   /* in zephyr\dts\arm\nordic\nrf52833.dtsi:491 */
			easydma-maxcnt-bits = < 0x10 >; /* in zephyr\dts\arm\nordic\nrf52833.dtsi:492 */
			compatible = "nordic,nrf-spim"; /* in ..\..\_Work\GitHub\PinTracker_NRF\pintracker_app\boards\decawave_dwm3001cdk.overlay:2 */
			status = "okay";                /* in ..\..\_Work\GitHub\PinTracker_NRF\pintracker_app\boards\decawave_dwm3001cdk.overlay:3 */
			pinctrl-0 = < &spi2_default >;  /* in ..\..\_Work\GitHub\PinTracker_NRF\pintracker_app\boards\decawave_dwm3001cdk.overlay:5 */
			pinctrl-1 = < &spi2_sleep >;    /* in ..\..\_Work\GitHub\PinTracker_NRF\pintracker_app\boards\decawave_dwm3001cdk.overlay:6 */
			pinctrl-names = "default",
			                "sleep";        /* in ..\..\_Work\GitHub\PinTracker_NRF\pintracker_app\boards\decawave_dwm3001cdk.overlay:7 */

			/* node '/soc/spi@40023000/dw3000@0' defined in ..\..\_Work\GitHub\PinTracker_NRF\pintracker_app\boards\decawave_dwm3001cdk.overlay:9 */
			dw3000: dw3000@0 {
				reg = < 0x0 >;                    /* in ..\..\_Work\GitHub\PinTracker_NRF\pintracker_app\boards\decawave_dwm3001cdk.overlay:10 */
				spi-max-frequency = < 0x7a1200 >; /* in ..\..\_Work\GitHub\PinTracker_NRF\pintracker_app\boards\decawave_dwm3001cdk.overlay:11 */
			};
		};

		/* node '/soc/rtc@40024000' defined in zephyr\dts\arm\nordic\nrf52833.dtsi:496 */
		rtc2: rtc@40024000 {
			compatible = "nordic,nrf-rtc"; /* in zephyr\dts\arm\nordic\nrf52833.dtsi:497 */
			reg = < 0x40024000 0x1000 >;   /* in zephyr\dts\arm\nordic\nrf52833.dtsi:498 */
			cc-num = < 0x4 >;              /* in zephyr\dts\arm\nordic\nrf52833.dtsi:499 */
			interrupts = < 0x24 0x1 >;     /* in zephyr\dts\arm\nordic\nrf52833.dtsi:500 */
			status = "disabled";           /* in zephyr\dts\arm\nordic\nrf52833.dtsi:501 */
			clock-frequency = < 0x8000 >;  /* in zephyr\dts\arm\nordic\nrf52833.dtsi:502 */
			prescaler = < 0x1 >;           /* in zephyr\dts\arm\nordic\nrf52833.dtsi:503 */
		};

		/* node '/soc/i2s@40025000' defined in zephyr\dts\arm\nordic\nrf52833.dtsi:506 */
		i2s0: i2s@40025000 {
			compatible = "nordic,nrf-i2s"; /* in zephyr\dts\arm\nordic\nrf52833.dtsi:507 */
			#address-cells = < 0x1 >;      /* in zephyr\dts\arm\nordic\nrf52833.dtsi:508 */
			#size-cells = < 0x0 >;         /* in zephyr\dts\arm\nordic\nrf52833.dtsi:509 */
			reg = < 0x40025000 0x1000 >;   /* in zephyr\dts\arm\nordic\nrf52833.dtsi:510 */
			interrupts = < 0x25 0x1 >;     /* in zephyr\dts\arm\nordic\nrf52833.dtsi:511 */
			status = "disabled";           /* in zephyr\dts\arm\nordic\nrf52833.dtsi:512 */
		};

		/* node '/soc/usbd@40027000' defined in zephyr\dts\arm\nordic\nrf52833.dtsi:515 */
		usbd: zephyr_udc0: usbd@40027000 {
			reg = < 0x40027000 0x1000 >;    /* in zephyr\dts\arm\nordic\nrf52833.dtsi:517 */
			interrupts = < 0x27 0x1 >;      /* in zephyr\dts\arm\nordic\nrf52833.dtsi:518 */
			num-bidir-endpoints = < 0x1 >;  /* in zephyr\dts\arm\nordic\nrf52833.dtsi:519 */
			num-in-endpoints = < 0x7 >;     /* in zephyr\dts\arm\nordic\nrf52833.dtsi:520 */
			num-out-endpoints = < 0x7 >;    /* in zephyr\dts\arm\nordic\nrf52833.dtsi:521 */
			num-isoin-endpoints = < 0x1 >;  /* in zephyr\dts\arm\nordic\nrf52833.dtsi:522 */
			num-isoout-endpoints = < 0x1 >; /* in zephyr\dts\arm\nordic\nrf52833.dtsi:523 */
			compatible = "nordic,nrf-usbd"; /* in zephyr\boards\qorvo\decawave_dwm3001cdk\decawave_dwm3001cdk.dts:163 */
			status = "okay";                /* in zephyr\boards\qorvo\decawave_dwm3001cdk\decawave_dwm3001cdk.dts:164 */
		};

		/* node '/soc/uart@40028000' defined in zephyr\dts\arm\nordic\nrf52833.dtsi:527 */
		uart1: uart@40028000 {
			compatible = "nordic,nrf-uarte"; /* in zephyr\dts\arm\nordic\nrf52833.dtsi:528 */
			reg = < 0x40028000 0x1000 >;     /* in zephyr\dts\arm\nordic\nrf52833.dtsi:529 */
			interrupts = < 0x28 0x1 >;       /* in zephyr\dts\arm\nordic\nrf52833.dtsi:530 */
			status = "disabled";             /* in zephyr\dts\arm\nordic\nrf52833.dtsi:531 */
		};

		/* node '/soc/pwm@4002d000' defined in zephyr\dts\arm\nordic\nrf52833.dtsi:534 */
		pwm3: pwm@4002d000 {
			compatible = "nordic,nrf-pwm"; /* in zephyr\dts\arm\nordic\nrf52833.dtsi:535 */
			reg = < 0x4002d000 0x1000 >;   /* in zephyr\dts\arm\nordic\nrf52833.dtsi:536 */
			interrupts = < 0x2d 0x1 >;     /* in zephyr\dts\arm\nordic\nrf52833.dtsi:537 */
			status = "disabled";           /* in zephyr\dts\arm\nordic\nrf52833.dtsi:538 */
			#pwm-cells = < 0x3 >;          /* in zephyr\dts\arm\nordic\nrf52833.dtsi:539 */
		};

		/* node '/soc/spi@4002f000' defined in zephyr\dts\arm\nordic\nrf52833.dtsi:542 */
		spi3: spi@4002f000 {
			#address-cells = < 0x1 >;       /* in zephyr\dts\arm\nordic\nrf52833.dtsi:544 */
			#size-cells = < 0x0 >;          /* in zephyr\dts\arm\nordic\nrf52833.dtsi:545 */
			reg = < 0x4002f000 0x1000 >;    /* in zephyr\dts\arm\nordic\nrf52833.dtsi:546 */
			interrupts = < 0x2f 0x1 >;      /* in zephyr\dts\arm\nordic\nrf52833.dtsi:547 */
			max-frequency = < 0x1e84800 >;  /* in zephyr\dts\arm\nordic\nrf52833.dtsi:548 */
			easydma-maxcnt-bits = < 0x10 >; /* in zephyr\dts\arm\nordic\nrf52833.dtsi:549 */
			rx-delay-supported;             /* in zephyr\dts\arm\nordic\nrf52833.dtsi:550 */
			rx-delay = < 0x2 >;             /* in zephyr\dts\arm\nordic\nrf52833.dtsi:551 */
			compatible = "nordic,nrf-spim"; /* in zephyr\boards\qorvo\decawave_dwm3001cdk\decawave_dwm3001cdk.dts:121 */
			status = "okay";                /* in zephyr\boards\qorvo\decawave_dwm3001cdk\decawave_dwm3001cdk.dts:122 */
			cs-gpios = < &gpio1 0x6 0x1 >;  /* in zephyr\boards\qorvo\decawave_dwm3001cdk\decawave_dwm3001cdk.dts:123 */
			pinctrl-0 = < &spi3_default >;  /* in zephyr\boards\qorvo\decawave_dwm3001cdk\decawave_dwm3001cdk.dts:125 */
			pinctrl-1 = < &spi3_sleep >;    /* in zephyr\boards\qorvo\decawave_dwm3001cdk\decawave_dwm3001cdk.dts:126 */
			pinctrl-names = "default",
			                "sleep";        /* in zephyr\boards\qorvo\decawave_dwm3001cdk\decawave_dwm3001cdk.dts:127 */
		};

		/* node '/soc/gpio@50000000' defined in zephyr\dts\arm\nordic\nrf52833.dtsi:555 */
		gpio0: gpio@50000000 {
			compatible = "nordic,nrf-gpio";              /* in zephyr\dts\arm\nordic\nrf52833.dtsi:556 */
			gpio-controller;                             /* in zephyr\dts\arm\nordic\nrf52833.dtsi:557 */
			reg = < 0x50000000 0x200 0x50000500 0x300 >; /* in zephyr\dts\arm\nordic\nrf52833.dtsi:558 */
			#gpio-cells = < 0x2 >;                       /* in zephyr\dts\arm\nordic\nrf52833.dtsi:560 */
			port = < 0x0 >;                              /* in zephyr\dts\arm\nordic\nrf52833.dtsi:562 */
			gpiote-instance = < &gpiote >;               /* in zephyr\dts\arm\nordic\nrf52833.dtsi:563 */
			status = "okay";                             /* in zephyr\boards\qorvo\decawave_dwm3001cdk\decawave_dwm3001cdk.dts:88 */
			phandle = < 0x6 >;                           /* in zephyr\boards\qorvo\decawave_dwm3001cdk\decawave_dwm3001cdk.dts:116 */
		};

		/* node '/soc/gpio@50000300' defined in zephyr\dts\arm\nordic\nrf52833.dtsi:566 */
		gpio1: gpio@50000300 {
			compatible = "nordic,nrf-gpio";              /* in zephyr\dts\arm\nordic\nrf52833.dtsi:567 */
			gpio-controller;                             /* in zephyr\dts\arm\nordic\nrf52833.dtsi:568 */
			reg = < 0x50000300 0x200 0x50000800 0x300 >; /* in zephyr\dts\arm\nordic\nrf52833.dtsi:569 */
			#gpio-cells = < 0x2 >;                       /* in zephyr\dts\arm\nordic\nrf52833.dtsi:571 */
			ngpios = < 0xa >;                            /* in zephyr\dts\arm\nordic\nrf52833.dtsi:572 */
			port = < 0x1 >;                              /* in zephyr\dts\arm\nordic\nrf52833.dtsi:574 */
			gpiote-instance = < &gpiote >;               /* in zephyr\dts\arm\nordic\nrf52833.dtsi:575 */
			status = "okay";                             /* in zephyr\boards\qorvo\decawave_dwm3001cdk\decawave_dwm3001cdk.dts:101 */
			phandle = < 0x9 >;                           /* in zephyr\boards\qorvo\decawave_dwm3001cdk\decawave_dwm3001cdk.dts:123 */
		};
	};

	/* node '/pin-controller' defined in zephyr\dts\vendor\nordic\nrf_common.dtsi:26 */
	pinctrl: pin-controller {
		compatible = "nordic,nrf-pinctrl"; /* in zephyr\dts\vendor\nordic\nrf_common.dtsi:31 */

		/* node '/pin-controller/uart0_default' defined in zephyr\boards\qorvo\decawave_dwm3001cdk\decawave_dwm3001cdk-pinctrl.dtsi:7 */
		uart0_default: uart0_default {
			phandle = < 0x2 >; /* in zephyr\boards\qorvo\decawave_dwm3001cdk\decawave_dwm3001cdk.dts:95 */

			/* node '/pin-controller/uart0_default/group1' defined in zephyr\boards\qorvo\decawave_dwm3001cdk\decawave_dwm3001cdk-pinctrl.dtsi:8 */
			group1 {
				psels = < 0x13 >,
				        < 0x100000f >; /* in zephyr\boards\qorvo\decawave_dwm3001cdk\decawave_dwm3001cdk-pinctrl.dtsi:9 */
			};
		};

		/* node '/pin-controller/uart0_sleep' defined in zephyr\boards\qorvo\decawave_dwm3001cdk\decawave_dwm3001cdk-pinctrl.dtsi:14 */
		uart0_sleep: uart0_sleep {
			phandle = < 0x3 >; /* in zephyr\boards\qorvo\decawave_dwm3001cdk\decawave_dwm3001cdk.dts:96 */

			/* node '/pin-controller/uart0_sleep/group1' defined in zephyr\boards\qorvo\decawave_dwm3001cdk\decawave_dwm3001cdk-pinctrl.dtsi:15 */
			group1 {
				psels = < 0x13 >,
				        < 0x100000f >; /* in zephyr\boards\qorvo\decawave_dwm3001cdk\decawave_dwm3001cdk-pinctrl.dtsi:16 */
				low-power-enable;      /* in zephyr\boards\qorvo\decawave_dwm3001cdk\decawave_dwm3001cdk-pinctrl.dtsi:18 */
			};
		};

		/* node '/pin-controller/i2c0_default' defined in zephyr\boards\qorvo\decawave_dwm3001cdk\decawave_dwm3001cdk-pinctrl.dtsi:22 */
		i2c0_default: i2c0_default {
			phandle = < 0x4 >; /* in zephyr\boards\qorvo\decawave_dwm3001cdk\decawave_dwm3001cdk.dts:109 */

			/* node '/pin-controller/i2c0_default/group1' defined in zephyr\boards\qorvo\decawave_dwm3001cdk\decawave_dwm3001cdk-pinctrl.dtsi:23 */
			group1 {
				psels = < 0xc000018 >,
				        < 0xb000024 >; /* in zephyr\boards\qorvo\decawave_dwm3001cdk\decawave_dwm3001cdk-pinctrl.dtsi:24 */
				bias-pull-up;          /* in zephyr\boards\qorvo\decawave_dwm3001cdk\decawave_dwm3001cdk-pinctrl.dtsi:26 */
			};
		};

		/* node '/pin-controller/i2c0_sleep' defined in zephyr\boards\qorvo\decawave_dwm3001cdk\decawave_dwm3001cdk-pinctrl.dtsi:30 */
		i2c0_sleep: i2c0_sleep {
			phandle = < 0x5 >; /* in zephyr\boards\qorvo\decawave_dwm3001cdk\decawave_dwm3001cdk.dts:110 */

			/* node '/pin-controller/i2c0_sleep/group1' defined in zephyr\boards\qorvo\decawave_dwm3001cdk\decawave_dwm3001cdk-pinctrl.dtsi:31 */
			group1 {
				psels = < 0xc000018 >,
				        < 0xb000024 >; /* in zephyr\boards\qorvo\decawave_dwm3001cdk\decawave_dwm3001cdk-pinctrl.dtsi:32 */
				low-power-enable;      /* in zephyr\boards\qorvo\decawave_dwm3001cdk\decawave_dwm3001cdk-pinctrl.dtsi:34 */
			};
		};

		/* node '/pin-controller/spi3_default' defined in zephyr\boards\qorvo\decawave_dwm3001cdk\decawave_dwm3001cdk-pinctrl.dtsi:38 */
		spi3_default: spi3_default {
			phandle = < 0xa >; /* in zephyr\boards\qorvo\decawave_dwm3001cdk\decawave_dwm3001cdk.dts:125 */

			/* node '/pin-controller/spi3_default/group1' defined in zephyr\boards\qorvo\decawave_dwm3001cdk\decawave_dwm3001cdk-pinctrl.dtsi:39 */
			group1 {
				psels = < 0x4000003 >,
				        < 0x5000008 >,
				        < 0x600001d >; /* in zephyr\boards\qorvo\decawave_dwm3001cdk\decawave_dwm3001cdk-pinctrl.dtsi:40 */
			};
		};

		/* node '/pin-controller/spi3_sleep' defined in zephyr\boards\qorvo\decawave_dwm3001cdk\decawave_dwm3001cdk-pinctrl.dtsi:46 */
		spi3_sleep: spi3_sleep {
			phandle = < 0xb >; /* in zephyr\boards\qorvo\decawave_dwm3001cdk\decawave_dwm3001cdk.dts:126 */

			/* node '/pin-controller/spi3_sleep/group1' defined in zephyr\boards\qorvo\decawave_dwm3001cdk\decawave_dwm3001cdk-pinctrl.dtsi:47 */
			group1 {
				psels = < 0x4000003 >,
				        < 0x5000008 >,
				        < 0x600001d >; /* in zephyr\boards\qorvo\decawave_dwm3001cdk\decawave_dwm3001cdk-pinctrl.dtsi:48 */
				low-power-enable;      /* in zephyr\boards\qorvo\decawave_dwm3001cdk\decawave_dwm3001cdk-pinctrl.dtsi:51 */
			};
		};

		/* node '/pin-controller/spi2_default' defined in ..\..\_Work\GitHub\PinTracker_NRF\pintracker_app\boards\decawave_dwm3001cdk.overlay:16 */
		spi2_default: spi2_default {
			phandle = < 0x7 >; /* in ..\..\_Work\GitHub\PinTracker_NRF\pintracker_app\boards\decawave_dwm3001cdk.overlay:5 */

			/* node '/pin-controller/spi2_default/group1' defined in ..\..\_Work\GitHub\PinTracker_NRF\pintracker_app\boards\decawave_dwm3001cdk.overlay:17 */
			group1 {
				psels = < 0x4000003 0x5000008 0x600001d >; /* in ..\..\_Work\GitHub\PinTracker_NRF\pintracker_app\boards\decawave_dwm3001cdk.overlay:18 */
			};
		};

		/* node '/pin-controller/spi2_sleep' defined in ..\..\_Work\GitHub\PinTracker_NRF\pintracker_app\boards\decawave_dwm3001cdk.overlay:26 */
		spi2_sleep: spi2_sleep {
			phandle = < 0x8 >; /* in ..\..\_Work\GitHub\PinTracker_NRF\pintracker_app\boards\decawave_dwm3001cdk.overlay:6 */

			/* node '/pin-controller/spi2_sleep/group1' defined in ..\..\_Work\GitHub\PinTracker_NRF\pintracker_app\boards\decawave_dwm3001cdk.overlay:27 */
			group1 {
				psels = < 0x4000003 0x5000008 0x600001d >; /* in ..\..\_Work\GitHub\PinTracker_NRF\pintracker_app\boards\decawave_dwm3001cdk.overlay:28 */
				low-power-enable;                          /* in ..\..\_Work\GitHub\PinTracker_NRF\pintracker_app\boards\decawave_dwm3001cdk.overlay:33 */
			};
		};
	};

	/* node '/entropy_bt_hci' defined in zephyr\dts\vendor\nordic\nrf_common.dtsi:34 */
	rng_hci: entropy_bt_hci {
		compatible = "zephyr,bt-hci-entropy"; /* in zephyr\dts\vendor\nordic\nrf_common.dtsi:35 */
		status = "disabled";                  /* in zephyr\dts\vendor\nordic\nrf_common.dtsi:36 */
	};

	/* node '/sw-pwm' defined in zephyr\dts\vendor\nordic\nrf_common.dtsi:39 */
	sw_pwm: sw-pwm {
		compatible = "nordic,nrf-sw-pwm"; /* in zephyr\dts\vendor\nordic\nrf_common.dtsi:40 */
		status = "disabled";              /* in zephyr\dts\vendor\nordic\nrf_common.dtsi:41 */
		generator = < &timer1 >;          /* in zephyr\dts\vendor\nordic\nrf_common.dtsi:42 */
		clock-prescaler = < 0x0 >;        /* in zephyr\dts\vendor\nordic\nrf_common.dtsi:43 */
		#pwm-cells = < 0x3 >;             /* in zephyr\dts\vendor\nordic\nrf_common.dtsi:44 */
	};

	/* node '/cpus' defined in zephyr\dts\arm\nordic\nrf52833.dtsi:19 */
	cpus {
		#address-cells = < 0x1 >; /* in zephyr\dts\arm\nordic\nrf52833.dtsi:20 */
		#size-cells = < 0x0 >;    /* in zephyr\dts\arm\nordic\nrf52833.dtsi:21 */

		/* node '/cpus/cpu@0' defined in zephyr\dts\arm\nordic\nrf52833.dtsi:23 */
		cpu@0 {
			device_type = "cpu";           /* in zephyr\dts\arm\nordic\nrf52833.dtsi:24 */
			compatible = "arm,cortex-m4f"; /* in zephyr\dts\arm\nordic\nrf52833.dtsi:25 */
			reg = < 0x0 >;                 /* in zephyr\dts\arm\nordic\nrf52833.dtsi:26 */
			#address-cells = < 0x1 >;      /* in zephyr\dts\arm\nordic\nrf52833.dtsi:27 */
			#size-cells = < 0x1 >;         /* in zephyr\dts\arm\nordic\nrf52833.dtsi:28 */

			/* node '/cpus/cpu@0/itm@e0000000' defined in zephyr\dts\arm\nordic\nrf52833.dtsi:30 */
			itm: itm@e0000000 {
				compatible = "arm,armv7m-itm";     /* in zephyr\dts\arm\nordic\nrf52833.dtsi:31 */
				reg = < 0xe0000000 0x1000 >;       /* in zephyr\dts\arm\nordic\nrf52833.dtsi:32 */
				swo-ref-frequency = < 0x1e84800 >; /* in zephyr\dts\arm\nordic\nrf52833.dtsi:33 */
			};
		};
	};

	/* node '/clocks' defined in zephyr\dts\arm\nordic\nrf52833.dtsi:38 */
	clocks {

		/* node '/clocks/hfxo' defined in zephyr\dts\arm\nordic\nrf52833.dtsi:39 */
		hfxo: hfxo {
			compatible = "nordic,nrf52-hfxo"; /* in zephyr\dts\arm\nordic\nrf52833.dtsi:40 */
			clock-frequency = < 0x3d09000 >;  /* in zephyr\dts\arm\nordic\nrf52833.dtsi:41 */
			startup-time-us = < 0x578 >;      /* in zephyr\dts\arm\nordic\nrf52833.dtsi:42 */
			#clock-cells = < 0x0 >;           /* in zephyr\dts\arm\nordic\nrf52833.dtsi:43 */
		};
	};

	/* node '/leds' defined in zephyr\boards\qorvo\decawave_dwm3001cdk\decawave_dwm3001cdk.dts:28 */
	leds {
		compatible = "gpio-leds"; /* in zephyr\boards\qorvo\decawave_dwm3001cdk\decawave_dwm3001cdk.dts:29 */

		/* node '/leds/led_0' defined in zephyr\boards\qorvo\decawave_dwm3001cdk\decawave_dwm3001cdk.dts:34 */
		led0: led_0 {
			gpios = < &gpio0 0x4 0x1 >; /* in zephyr\boards\qorvo\decawave_dwm3001cdk\decawave_dwm3001cdk.dts:35 */
			label = "D9 green LED";     /* in zephyr\boards\qorvo\decawave_dwm3001cdk\decawave_dwm3001cdk.dts:36 */
		};

		/* node '/leds/led_1' defined in zephyr\boards\qorvo\decawave_dwm3001cdk\decawave_dwm3001cdk.dts:39 */
		led1: led_1 {
			gpios = < &gpio0 0xe 0x1 >; /* in zephyr\boards\qorvo\decawave_dwm3001cdk\decawave_dwm3001cdk.dts:40 */
			label = "D12 red LED";      /* in zephyr\boards\qorvo\decawave_dwm3001cdk\decawave_dwm3001cdk.dts:41 */
		};

		/* node '/leds/led_2' defined in zephyr\boards\qorvo\decawave_dwm3001cdk\decawave_dwm3001cdk.dts:44 */
		led2: led_2 {
			gpios = < &gpio0 0x16 0x1 >; /* in zephyr\boards\qorvo\decawave_dwm3001cdk\decawave_dwm3001cdk.dts:45 */
			label = "D11 red LED";       /* in zephyr\boards\qorvo\decawave_dwm3001cdk\decawave_dwm3001cdk.dts:46 */
		};

		/* node '/leds/led_3' defined in zephyr\boards\qorvo\decawave_dwm3001cdk\decawave_dwm3001cdk.dts:49 */
		led3: led_3 {
			gpios = < &gpio0 0x5 0x1 >; /* in zephyr\boards\qorvo\decawave_dwm3001cdk\decawave_dwm3001cdk.dts:50 */
			label = "D10 blue LED";     /* in zephyr\boards\qorvo\decawave_dwm3001cdk\decawave_dwm3001cdk.dts:51 */
		};
	};

	/* node '/buttons' defined in zephyr\boards\qorvo\decawave_dwm3001cdk\decawave_dwm3001cdk.dts:55 */
	buttons {
		compatible = "gpio-keys"; /* in zephyr\boards\qorvo\decawave_dwm3001cdk\decawave_dwm3001cdk.dts:56 */

		/* node '/buttons/button_2' defined in zephyr\boards\qorvo\decawave_dwm3001cdk\decawave_dwm3001cdk.dts:60 */
		button2: button_2 {
			gpios = < &gpio0 0x2 0x11 >;    /* in zephyr\boards\qorvo\decawave_dwm3001cdk\decawave_dwm3001cdk.dts:61 */
			label = "Push button switch 2"; /* in zephyr\boards\qorvo\decawave_dwm3001cdk\decawave_dwm3001cdk.dts:62 */
			zephyr,code = < 0x2 >;          /* in zephyr\boards\qorvo\decawave_dwm3001cdk\decawave_dwm3001cdk.dts:63 */
		};
	};
};
